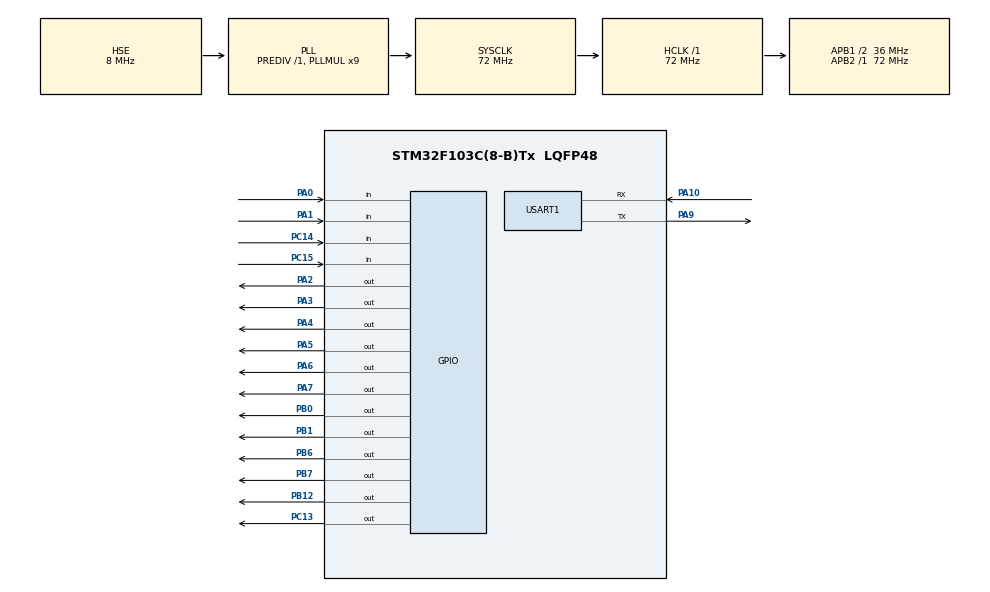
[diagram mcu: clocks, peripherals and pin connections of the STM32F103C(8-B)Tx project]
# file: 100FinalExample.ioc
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FREERTOS.Tasks01=LoopTask,24,64,vLoopTask,As weak,NULL,Dynamic,NULL,NULL;LedTask,8,64,vLedTask,As weak,NULL,Dynamic,NULL,NULL;OledTask,8,64,vOledTask,As weak,NULL,Dynamic,NULL,NULL;ButtonProcessTa,8,64,vButtonProcessTask,As weak,NULL,Dynamic,NULL,NULL;Dht11Task,16,64,vDht11Task,As weak,NULL,Dynamic,NULL,NULL;UartTxTask,8,64,vUartTxTask,As weak,NULL,Dynamic,NULL,NULL;UartRxTask,8,64,vUartRxTask,As weak,NULL,Dynamic,NULL,NULL;UartCmdInterpre,8,64,vUartCmdInterpreterTask,As weak,NULL,Dynamic,NULL,NULL
FREERTOS.configMINIMAL_STACK_SIZE=64
FREERTOS.configTOTAL_HEAP_SIZE=4096
Mcu.Family=STM32F1
Mcu.Name=STM32F103C(8-B)Tx
Mcu.Package=LQFP48
NVIC.PriorityGroup=NVIC_PRIORITYGROUP_4
NVIC.USART1_IRQn=true\:5\:0\:false\:false\:true\:true\:true\:true
PA0-WKUP.GPIO_PuPd=GPIO_PULLUP
PA0-WKUP.Signal=GPIO_Input
PA1.GPIO_PuPd=GPIO_PULLUP
PA1.Signal=GPIO_Input
PA10.Mode=Asynchronous
PA10.Signal=USART1_RX
PA13.Mode=Serial_Wire
PA13.Signal=SYS_JTMS-SWDIO
PA14.Mode=Serial_Wire
PA14.Signal=SYS_JTCK-SWCLK
PA2.Signal=GPIO_Output
PA3.Signal=GPIO_Output
PA4.Signal=GPIO_Output
PA5.Signal=GPIO_Output
PA6.Signal=GPIO_Output
PA7.Signal=GPIO_Output
PA9.Mode=Asynchronous
PA9.Signal=USART1_TX
PB0.Signal=GPIO_Output
PB1.Signal=GPIO_Output
PB12.GPIO_PuPd=GPIO_PULLUP
PB12.GPIO_Speed=GPIO_SPEED_FREQ_HIGH
PB12.Signal=GPIO_Output
PB6.GPIO_PuPd=GPIO_PULLUP
PB6.GPIO_Speed=GPIO_SPEED_FREQ_HIGH
PB6.Signal=GPIO_Output
PB7.GPIO_PuPd=GPIO_PULLUP
PB7.GPIO_Speed=GPIO_SPEED_FREQ_HIGH
PB7.Signal=GPIO_Output
PC13-TAMPER-RTC.Signal=GPIO_Output
PC14-OSC32_IN.GPIO_PuPd=GPIO_PULLUP
PC14-OSC32_IN.Signal=GPIO_Input
PC15-OSC32_OUT.GPIO_PuPd=GPIO_PULLUP
PC15-OSC32_OUT.Signal=GPIO_Input
PD0-OSC_IN.Mode=HSE-External-Oscillator
PD0-OSC_IN.Signal=RCC_OSC_IN
PD1-OSC_OUT.Mode=HSE-External-Oscillator
PD1-OSC_OUT.Signal=RCC_OSC_OUT
ProjectManager.HeapSize=0x200
ProjectManager.StackSize=0x400
ProjectManager.TargetToolchain=MDK-ARM V5.27
RCC.AHBFreq_Value=72000000
RCC.APB1CLKDivider=RCC_HCLK_DIV2
RCC.APB1Freq_Value=36000000
RCC.APB1TimFreq_Value=72000000
RCC.APB2Freq_Value=72000000
RCC.APB2TimFreq_Value=72000000
RCC.HCLKFreq_Value=72000000
RCC.PLLMUL=RCC_PLL_MUL9
RCC.PLLSourceVirtual=RCC_PLLSOURCE_HSE
RCC.SYSCLKFreq_VALUE=72000000
RCC.SYSCLKSource=RCC_SYSCLKSOURCE_PLLCLK
RCC.USBFreq_Value=72000000
USART1.VirtualMode=VM_ASYNC
VP_FREERTOS_VS_CMSIS_V2.Mode=CMSIS_V2
board=custom

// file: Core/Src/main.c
/* USER CODE BEGIN Header */
/**
  ******************************************************************************
  * @file           : main.c
  * @brief          : Main program body
  ******************************************************************************
  * @attention
  *
  * <h2><center>&copy; Copyright (c) 2025 STMicroelectronics.
  * All rights reserved.</center></h2>
  *
  * This software component is licensed by ST under Ultimate Liberty license
  * SLA0044, the "License"; You may not use this file except in compliance with
  * the License. You may obtain a copy of the License at:
  *                             www.st.com/SLA0044
  *
  ******************************************************************************
  */
/* USER CODE END Header */
#include "main.h"
#include "cmsis_os.h"

UART_HandleTypeDef huart1;

/* Definitions for LoopTask */
osThreadId_t LoopTaskHandle;
const osThreadAttr_t LoopTask_attributes = {
  .name = "LoopTask",
  .priority = (osPriority_t) osPriorityNormal,
  .stack_size = 64 * 4
};
/* Definitions for LedTask */
osThreadId_t LedTaskHandle;
const osThreadAttr_t LedTask_attributes = {
  .name = "LedTask",
  .priority = (osPriority_t) osPriorityLow,
  .stack_size = 64 * 4
};
/* Definitions for OledTask */
osThreadId_t OledTaskHandle;
const osThreadAttr_t OledTask_attributes = {
  .name = "OledTask",
  .priority = (osPriority_t) osPriorityLow,
  .stack_size = 64 * 4
};
/* Definitions for ButtonProcessTa */
osThreadId_t ButtonProcessTaHandle;
const osThreadAttr_t ButtonProcessTa_attributes = {
  .name = "ButtonProcessTa",
  .priority = (osPriority_t) osPriorityLow,
  .stack_size = 64 * 4
};
/* Definitions for Dht11Task */
osThreadId_t Dht11TaskHandle;
const osThreadAttr_t Dht11Task_attributes = {
  .name = "Dht11Task",
  .priority = (osPriority_t) osPriorityBelowNormal,
  .stack_size = 64 * 4
};
/* Definitions for UartTxTask */
osThreadId_t UartTxTaskHandle;
const osThreadAttr_t UartTxTask_attributes = {
  .name = "UartTxTask",
  .priority = (osPriority_t) osPriorityLow,
  .stack_size = 64 * 4
};
/* Definitions for UartRxTask */
osThreadId_t UartRxTaskHandle;
const osThreadAttr_t UartRxTask_attributes = {
  .name = "UartRxTask",
  .priority = (osPriority_t) osPriorityLow,
  .stack_size = 64 * 4
};
/* Definitions for UartCmdInterpre */
osThreadId_t UartCmdInterpreHandle;
const osThreadAttr_t UartCmdInterpre_attributes = {
  .name = "UartCmdInterpre",
  .priority = (osPriority_t) osPriorityLow,
  .stack_size = 64 * 4
};

void SystemClock_Config(void);
static void MX_GPIO_Init(void);
static void MX_USART1_UART_Init(void);
void vLoopTask(void *argument);
void vLedTask(void *argument);
void vOledTask(void *argument);
void vButtonProcessTask(void *argument);
void vDht11Task(void *argument);
void vUartTxTask(void *argument);
void vUartRxTask(void *argument);
void vUartCmdInterpreterTask(void *argument);

int main(void)
{

  /* MCU Configuration--------------------------------------------------------*/

  /* Reset of all peripherals, Initializes the Flash interface and the Systick. */
  HAL_Init();

  /* Configure the system clock */
  SystemClock_Config();

  /* Initialize all configured peripherals */
  MX_GPIO_Init();
  MX_USART1_UART_Init();

  /* Init scheduler */
  osKernelInitialize();

  /* Create the thread(s) */
  /* creation of LoopTask */
  LoopTaskHandle = osThreadNew(vLoopTask, NULL, &LoopTask_attributes);

  /* creation of LedTask */
  LedTaskHandle = osThreadNew(vLedTask, NULL, &LedTask_attributes);

  /* creation of OledTask */
  OledTaskHandle = osThreadNew(vOledTask, NULL, &OledTask_attributes);

  /* creation of ButtonProcessTa */
  ButtonProcessTaHandle = osThreadNew(vButtonProcessTask, NULL, &ButtonProcessTa_attributes);

  /* creation of Dht11Task */
  Dht11TaskHandle = osThreadNew(vDht11Task, NULL, &Dht11Task_attributes);

  /* creation of UartTxTask */
  UartTxTaskHandle = osThreadNew(vUartTxTask, NULL, &UartTxTask_attributes);

  /* creation of UartRxTask */
  UartRxTaskHandle = osThreadNew(vUartRxTask, NULL, &UartRxTask_attributes);

  /* creation of UartCmdInterpre */
  UartCmdInterpreHandle = osThreadNew(vUartCmdInterpreterTask, NULL, &UartCmdInterpre_attributes);

  /* Start scheduler */
  osKernelStart();

  /* We should never get here as control is now taken by the scheduler */
  /* Infinite loop */
  while (1)
  {

  }
}

void SystemClock_Config(void)
{
  RCC_OscInitTypeDef RCC_OscInitStruct = {0};
  RCC_ClkInitTypeDef RCC_ClkInitStruct = {0};

  /** Initializes the RCC Oscillators according to the specified parameters
  * in the RCC_OscInitTypeDef structure.
  */
  RCC_OscInitStruct.OscillatorType = RCC_OSCILLATORTYPE_HSE;
  RCC_OscInitStruct.HSEState = RCC_HSE_ON;
  RCC_OscInitStruct.HSEPredivValue = RCC_HSE_PREDIV_DIV1;
  RCC_OscInitStruct.HSIState = RCC_HSI_ON;
  RCC_OscInitStruct.PLL.PLLState = RCC_PLL_ON;
  RCC_OscInitStruct.PLL.PLLSource = RCC_PLLSOURCE_HSE;
  RCC_OscInitStruct.PLL.PLLMUL = RCC_PLL_MUL9;
  if (HAL_RCC_OscConfig(&RCC_OscInitStruct) != HAL_OK)
  {
    Error_Handler();
  }
  /** Initializes the CPU, AHB and APB buses clocks
  */
  RCC_ClkInitStruct.ClockType = RCC_CLOCKTYPE_HCLK|RCC_CLOCKTYPE_SYSCLK
                              |RCC_CLOCKTYPE_PCLK1|RCC_CLOCKTYPE_PCLK2;
  RCC_ClkInitStruct.SYSCLKSource = RCC_SYSCLKSOURCE_PLLCLK;
  RCC_ClkInitStruct.AHBCLKDivider = RCC_SYSCLK_DIV1;
  RCC_ClkInitStruct.APB1CLKDivider = RCC_HCLK_DIV2;
  RCC_ClkInitStruct.APB2CLKDivider = RCC_HCLK_DIV1;

  if (HAL_RCC_ClockConfig(&RCC_ClkInitStruct, FLASH_LATENCY_2) != HAL_OK)
  {
    Error_Handler();
  }
}

static void MX_USART1_UART_Init(void)
{

  huart1.Instance = USART1;
  huart1.Init.BaudRate = 115200;
  huart1.Init.WordLength = UART_WORDLENGTH_8B;
  huart1.Init.StopBits = UART_STOPBITS_1;
  huart1.Init.Parity = UART_PARITY_NONE;
  huart1.Init.Mode = UART_MODE_TX_RX;
  huart1.Init.HwFlowCtl = UART_HWCONTROL_NONE;
  huart1.Init.OverSampling = UART_OVERSAMPLING_16;
  if (HAL_UART_Init(&huart1) != HAL_OK)
  {
    Error_Handler();
  }
  /* USER CODE BEGIN USART1_Init 2 */
//  __HAL_UART_ENABLE_IT(&huart1, UART_IT_RXNE);      // UART1 接收中断使能
//  __HAL_UART_ENABLE(&huart1);                       // UART1 使能
  /* USER CODE END USART1_Init 2 */

}

static void MX_GPIO_Init(void)
{
  GPIO_InitTypeDef GPIO_InitStruct = {0};

  /* GPIO Ports Clock Enable */
  __HAL_RCC_GPIOC_CLK_ENABLE();
  __HAL_RCC_GPIOD_CLK_ENABLE();
  __HAL_RCC_GPIOA_CLK_ENABLE();
  __HAL_RCC_GPIOB_CLK_ENABLE();

  /*Configure GPIO pin Output Level */
  HAL_GPIO_WritePin(GPIOC, GPIO_PIN_13, GPIO_PIN_RESET);

  /*Configure GPIO pin Output Level */
  HAL_GPIO_WritePin(GPIOA, GPIO_PIN_2|GPIO_PIN_3|GPIO_PIN_4|GPIO_PIN_5
                          |GPIO_PIN_6|GPIO_PIN_7, GPIO_PIN_RESET);

  /*Configure GPIO pin Output Level */
  HAL_GPIO_WritePin(GPIOB, GPIO_PIN_0|GPIO_PIN_1|GPIO_PIN_12|GPIO_PIN_6
                          |GPIO_PIN_7, GPIO_PIN_RESET);

  /*Configure GPIO pin : PC13 */
  GPIO_InitStruct.Pin = GPIO_PIN_13;
  GPIO_InitStruct.Mode = GPIO_MODE_OUTPUT_PP;
  GPIO_InitStruct.Pull = GPIO_NOPULL;
  GPIO_InitStruct.Speed = GPIO_SPEED_FREQ_LOW;
  HAL_GPIO_Init(GPIOC, &GPIO_InitStruct);

  /*Configure GPIO pins : PC14 PC15 */
  GPIO_InitStruct.Pin = GPIO_PIN_14|GPIO_PIN_15;
  GPIO_InitStruct.Mode = GPIO_MODE_INPUT;
  GPIO_InitStruct.Pull = GPIO_PULLUP;
  HAL_GPIO_Init(GPIOC, &GPIO_InitStruct);

  /*Configure GPIO pins : PA0 PA1 */
  GPIO_InitStruct.Pin = GPIO_PIN_0|GPIO_PIN_1;
  GPIO_InitStruct.Mode = GPIO_MODE_INPUT;
  GPIO_InitStruct.Pull = GPIO_PULLUP;
  HAL_GPIO_Init(GPIOA, &GPIO_InitStruct);

  /*Configure GPIO pins : PA2 PA3 PA4 PA5
                           PA6 PA7 */
  GPIO_InitStruct.Pin = GPIO_PIN_2|GPIO_PIN_3|GPIO_PIN_4|GPIO_PIN_5
                          |GPIO_PIN_6|GPIO_PIN_7;
  GPIO_InitStruct.Mode = GPIO_MODE_OUTPUT_PP;
  GPIO_InitStruct.Pull = GPIO_NOPULL;
  GPIO_InitStruct.Speed = GPIO_SPEED_FREQ_LOW;
  HAL_GPIO_Init(GPIOA, &GPIO_InitStruct);

  /*Configure GPIO pins : PB0 PB1 */
  GPIO_InitStruct.Pin = GPIO_PIN_0|GPIO_PIN_1;
  GPIO_InitStruct.Mode = GPIO_MODE_OUTPUT_PP;
  GPIO_InitStruct.Pull = GPIO_NOPULL;
  GPIO_InitStruct.Speed = GPIO_SPEED_FREQ_LOW;
  HAL_GPIO_Init(GPIOB, &GPIO_InitStruct);

  /*Configure GPIO pins : PB12 PB6 PB7 */
  GPIO_InitStruct.Pin = GPIO_PIN_12|GPIO_PIN_6|GPIO_PIN_7;
  GPIO_InitStruct.Mode = GPIO_MODE_OUTPUT_PP;
  GPIO_InitStruct.Pull = GPIO_PULLUP;
  GPIO_InitStruct.Speed = GPIO_SPEED_FREQ_HIGH;
  HAL_GPIO_Init(GPIOB, &GPIO_InitStruct);

}

__weak void vLoopTask(void *argument)
{
  for(;;)
  {
    osDelay(1);
  }
}

__weak void vLedTask(void *argument)
{
  for(;;)
  {
    osDelay(1);
  }
}

__weak void vOledTask(void *argument)
{
  for(;;)
  {
    osDelay(1);
  }
}

__weak void vButtonProcessTask(void *argument)
{
  for(;;)
  {
    osDelay(1);
  }
}

__weak void vDht11Task(void *argument)
{
  for(;;)
  {
    osDelay(1);
  }
}

__weak void vUartTxTask(void *argument)
{
  for(;;)
  {
    osDelay(1);
  }
}

__weak void vUartRxTask(void *argument)
{
  for(;;)
  {
    osDelay(1);
  }
}

__weak void vUartCmdInterpreterTask(void *argument)
{
  for(;;)
  {
    osDelay(1);
  }
}

void Error_Handler(void)
{
  __disable_irq();
  while (1)
  {
  }
}

/************************ (C) COPYRIGHT STMicroelectronics *****END OF FILE****/
